AUTOSAR XML (schema 4-3-0)
package /ComponentTypes
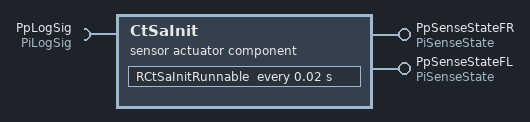
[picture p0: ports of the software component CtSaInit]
  sensor actuator sw component type CtSaInit
    provide port PpSenseStateFR: nonqueued-sender-com-spec{data-element=DePiSenseState, init-value=0}, provided-interface=PiSenseState
    require port PpLogSig: nonqueued-receiver-com-spec{data-element=DePiLedState, filter=data-filter-type=ALWAYS, init-value=0}, required-interface=PiLogSig
    provide port PpSenseStateFL: nonqueued-sender-com-spec=DePiSenseState, provided-interface=PiSenseState
    behavior CtSaInit_InternalBehavior: supports-multiple-instantiation=true
      timing event TMT_RCtSaInitRunnable: start-on-event=RCtSaInitRunnable, period=0.02
      runnable RCtSaInitRunnable
        data-receive-point-by-arguments:
          access REC_PiLogSig_DePiLedState: accessed-variable=PpLogSig.DePiLedState
        data-send-points:
          access SEND_PpSenseState_DePiSenseState: accessed-variable=PpSenseStateFR.DePiSenseState
  swc implementation CtSaInit_Implementation: behavior=CtSaInit_InternalBehavior
